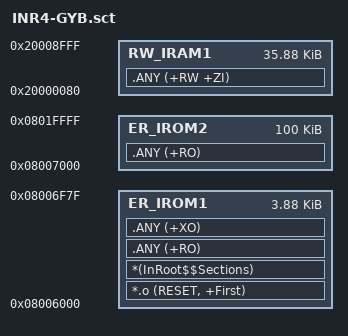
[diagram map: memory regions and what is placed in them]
; *************************************************************
; *** Scatter-Loading Description File generated by uVision ***
; *************************************************************

LR_IROM1 0x08006000 0x00000F80  {    ; load region size_region
  ER_IROM1 0x08006000 0x00000F80  {  ; load address = execution address
   *.o (RESET, +First)
   *(InRoot$$Sections)
   .ANY (+RO)
   .ANY (+XO)
  }
  RW_IRAM1 0x20000080 0x00008F80  {  ; RW data
   .ANY (+RW +ZI)
  }
}

LR_IROM2 0x08007000 0x00019000  {
  ER_IROM2 0x08007000 0x00019000  {  ; load address = execution address
   .ANY (+RO)
  }
}
